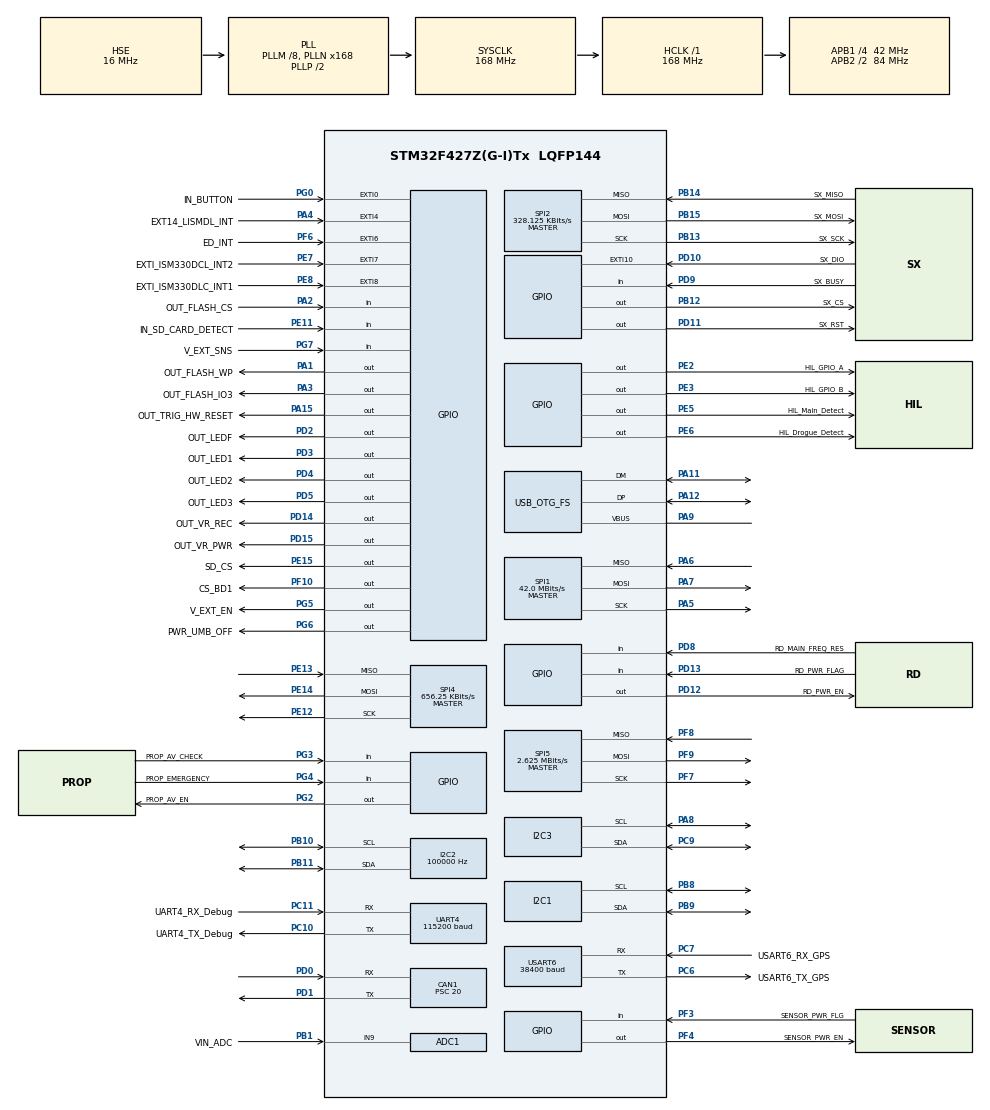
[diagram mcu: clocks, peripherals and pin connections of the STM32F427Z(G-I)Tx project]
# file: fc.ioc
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ADC1.Channel-1\#ChannelRegularConversion=ADC_CHANNEL_9
ADC1.NbrOfConversionFlag=1
ADC1.Rank-1\#ChannelRegularConversion=1
ADC1.SamplingTime-1\#ChannelRegularConversion=ADC_SAMPLETIME_3CYCLES
ADC1.master=1
CAN1.ABOM=DISABLE
CAN1.AWUM=DISABLE
CAN1.BS1=CAN_BS1_12TQ
CAN1.BS2=CAN_BS2_8TQ
CAN1.CalculateBaudRate=100000
CAN1.CalculateTimeBit=10000
CAN1.CalculateTimeQuantum=476.1904761904762
CAN1.Mode=CAN_MODE_NORMAL
CAN1.NART=DISABLE
CAN1.Prescaler=20
CAN1.RFLM=DISABLE
CAN1.SJW=CAN_SJW_1TQ
CAN1.TTCM=DISABLE
CAN1.TXFP=DISABLE
Dma.Request0=USART6_RX
Dma.Request1=SPI2_TX
Dma.Request2=SPI2_RX
Dma.SPI2_RX.2.Direction=DMA_PERIPH_TO_MEMORY
Dma.SPI2_RX.2.FIFOMode=DMA_FIFOMODE_DISABLE
Dma.SPI2_RX.2.Instance=DMA1_Stream3
Dma.SPI2_RX.2.MemDataAlignment=DMA_MDATAALIGN_BYTE
Dma.SPI2_RX.2.MemInc=DMA_MINC_ENABLE
Dma.SPI2_RX.2.Mode=DMA_NORMAL
Dma.SPI2_RX.2.PeriphDataAlignment=DMA_PDATAALIGN_BYTE
Dma.SPI2_RX.2.PeriphInc=DMA_PINC_DISABLE
Dma.SPI2_RX.2.Priority=DMA_PRIORITY_VERY_HIGH
Dma.SPI2_TX.1.Direction=DMA_MEMORY_TO_PERIPH
Dma.SPI2_TX.1.FIFOMode=DMA_FIFOMODE_DISABLE
Dma.SPI2_TX.1.Instance=DMA1_Stream4
Dma.SPI2_TX.1.MemDataAlignment=DMA_MDATAALIGN_BYTE
Dma.SPI2_TX.1.MemInc=DMA_MINC_ENABLE
Dma.SPI2_TX.1.Mode=DMA_NORMAL
Dma.SPI2_TX.1.PeriphDataAlignment=DMA_PDATAALIGN_BYTE
Dma.SPI2_TX.1.PeriphInc=DMA_PINC_DISABLE
Dma.SPI2_TX.1.Priority=DMA_PRIORITY_VERY_HIGH
Dma.USART6_RX.0.Direction=DMA_PERIPH_TO_MEMORY
Dma.USART6_RX.0.FIFOMode=DMA_FIFOMODE_DISABLE
Dma.USART6_RX.0.Instance=DMA2_Stream1
Dma.USART6_RX.0.MemDataAlignment=DMA_MDATAALIGN_BYTE
Dma.USART6_RX.0.MemInc=DMA_MINC_ENABLE
Dma.USART6_RX.0.Mode=DMA_NORMAL
Dma.USART6_RX.0.PeriphDataAlignment=DMA_PDATAALIGN_BYTE
Dma.USART6_RX.0.PeriphInc=DMA_PINC_DISABLE
Dma.USART6_RX.0.Priority=DMA_PRIORITY_MEDIUM
FATFS._CODE_PAGE=850
FATFS._FS_EXFAT=0
FATFS._FS_LOCK=2
FATFS._FS_MINIMIZE=0
FATFS._FS_NOFSINFO=0
FATFS._FS_NORTC=0
FATFS._FS_READONLY=0
FATFS._FS_REENTRANT=1
FATFS._FS_RPATH=0
FATFS._FS_TIMEOUT=1000
FATFS._FS_TINY=0
FATFS._LFN_UNICODE=0
FATFS._MAX_LFN=255
FATFS._MAX_SS=512
FATFS._MIN_SS=512
FATFS._MULTI_PARTITION=0
FATFS._STRF_ENCODE=3
FATFS._USE_CHMOD=0
FATFS._USE_EXPAND=0
FATFS._USE_FASTSEEK=1
FATFS._USE_FIND=0
FATFS._USE_FORWARD=0
FATFS._USE_LABEL=0
FATFS._USE_LFN=0
FATFS._USE_MKFS=1
FATFS._USE_STRFUNC=2
FATFS._USE_TRIM=0
FATFS._VOLUMES=1
FREERTOS.Tasks01=Telemetry,24,1024,StartTelemetry,Default,NULL,Dynamic,NULL,NULL;Radio,40,512,StartRadio,Default,NULL,Dynamic,NULL,NULL;Watchdog,48,512,StartWatchdog,Default,NULL,Dynamic,NULL,NULL;CAN,24,1024,StartCAN,Default,NULL,Dynamic,NULL,NULL
FREERTOS.configMINIMAL_STACK_SIZE=512
FREERTOS.configTIMER_TASK_PRIORITY=1
FREERTOS.configTIMER_TASK_STACK_DEPTH=512
FREERTOS.configUSE_DAEMON_TASK_STARTUP_HOOK=1
FREERTOS.configUSE_NEWLIB_REENTRANT=1
I2C2.AddressingMode=I2C_ADDRESSINGMODE_7BIT
I2C2.Analog_Filter=I2C_ANALOGFILTER_ENABLE
I2C2.ClockSpeed=100000
I2C2.DualAddressMode=I2C_DUALADDRESS_DISABLE
I2C2.GeneralCallMode=I2C_GENERALCALL_DISABLE
I2C2.I2C_Coeff_DF=0
I2C2.I2C_Mode=I2C_Standard
I2C2.NoStretchMode=I2C_NOSTRETCH_DISABLE
I2C2.OwnAddress=0
IWDG.Prescaler=IWDG_PRESCALER_32
IWDG.Reload=2999
Mcu.Family=STM32F4
Mcu.Name=STM32F427Z(G-I)Tx
Mcu.Package=LQFP144
NVIC.CAN1_RX0_IRQn=true\:5\:0\:false\:false\:true\:true\:true\:true\:true
NVIC.CAN1_RX1_IRQn=true\:5\:0\:false\:false\:true\:true\:true\:true\:true
NVIC.DMA1_Stream3_IRQn=true\:5\:0\:false\:false\:true\:true\:false\:true\:true
NVIC.DMA1_Stream4_IRQn=true\:5\:0\:false\:false\:true\:true\:false\:true\:true
NVIC.DMA2_Stream1_IRQn=true\:5\:0\:false\:false\:true\:false\:false\:true\:true
NVIC.EXTI15_10_IRQn=true\:5\:0\:false\:false\:true\:true\:true\:true\:true
NVIC.EXTI4_IRQn=true\:5\:0\:false\:false\:true\:true\:true\:true\:true
NVIC.EXTI9_5_IRQn=true\:5\:0\:false\:false\:true\:true\:true\:true\:true
NVIC.OTG_FS_IRQn=true\:5\:0\:false\:false\:true\:true\:false\:true\:true
NVIC.PriorityGroup=NVIC_PRIORITYGROUP_4
NVIC.TIM2_IRQn=true\:5\:0\:false\:false\:true\:true\:true\:true\:true
NVIC.TIM3_IRQn=true\:5\:0\:false\:false\:true\:true\:true\:true\:true
NVIC.TIM4_IRQn=true\:5\:0\:true\:false\:true\:true\:true\:true\:true
NVIC.TIM5_IRQn=true\:5\:0\:true\:false\:true\:true\:true\:true\:true
NVIC.UART4_IRQn=true\:5\:0\:true\:false\:true\:true\:true\:true\:true
PA1.GPIO_Label=OUT_FLASH_WP
PA1.Signal=GPIO_Output
PA11.Mode=Device_Only
PA11.Signal=USB_OTG_FS_DM
PA12.Mode=Device_Only
PA12.Signal=USB_OTG_FS_DP
PA13.Mode=Trace_Asynchronous_SW
PA13.Signal=SYS_JTMS-SWDIO
PA14.Mode=Trace_Asynchronous_SW
PA14.Signal=SYS_JTCK-SWCLK
PA15.GPIO_Label=OUT_TRIG_HW_RESET
PA15.Signal=GPIO_Output
PA2.GPIO_Label=OUT_FLASH_CS
PA2.Signal=GPIO_Input
PA3.GPIO_Label=OUT_FLASH_IO3
PA3.Signal=GPIO_Output
PA4.GPIO_Label=EXT14_LISMDL_INT
PA4.Signal=GPXTI4
PA5.Mode=Full_Duplex_Master
PA5.Signal=SPI1_SCK
PA6.Mode=Full_Duplex_Master
PA6.Signal=SPI1_MISO
PA7.Mode=Full_Duplex_Master
PA7.Signal=SPI1_MOSI
PA8.GPIO_Pu=GPIO_PULLUP
PA8.Mode=I2C
PA8.Signal=I2C3_SCL
PA9.Mode=Activate_VBUS
PA9.Signal=USB_OTG_FS_VBUS
PB1.GPIO_Label=VIN_ADC
PB1.Signal=ADCx_IN9
PB10.GPIO_Pu=GPIO_PULLUP
PB10.Mode=I2C
PB10.Signal=I2C2_SCL
PB11.GPIO_Pu=GPIO_PULLUP
PB11.Mode=I2C
PB11.Signal=I2C2_SDA
PB12.GPIO_Label=SX_CS
PB12.GPIO_PuPd=GPIO_PULLUP
PB12.GPIO_Speed=GPIO_SPEED_FREQ_VERY_HIGH
PB12.Signal=GPIO_Output
PB13.GPIO_Label=SX_SCK
PB13.GPIO_PuPd=GPIO_NOPULL
PB13.Mode=Full_Duplex_Master
PB13.Signal=SPI2_SCK
PB14.GPIO_Label=SX_MISO
PB14.GPIO_PuPd=GPIO_NOPULL
PB14.Mode=Full_Duplex_Master
PB14.Signal=SPI2_MISO
PB15.GPIO_Label=SX_MOSI
PB15.GPIO_PuPd=GPIO_NOPULL
PB15.Mode=Full_Duplex_Master
PB15.Signal=SPI2_MOSI
PB3.Mode=Trace_Asynchronous_SW
PB3.Signal=SYS_JTDO-SWO
PB8.GPIO_Pu=GPIO_PULLUP
PB8.Mode=I2C
PB8.Signal=I2C1_SCL
PB9.GPIO_Pu=GPIO_PULLUP
PB9.Mode=I2C
PB9.Signal=I2C1_SDA
PC10.GPIO_Label=UART4_TX_Debug
PC10.Mode=Asynchronous
PC10.Signal=UART4_TX
PC11.GPIO_Label=UART4_RX_Debug
PC11.Mode=Asynchronous
PC11.Signal=UART4_RX
PC14/OSC32_IN.Mode=LSE-External-Oscillator
PC14/OSC32_IN.Signal=RCC_OSC32_IN
PC15/OSC32_OUT.Mode=LSE-External-Oscillator
PC15/OSC32_OUT.Signal=RCC_OSC32_OUT
PC6.GPIO_Label=USART6_TX_GPS
PC6.Mode=Asynchronous
PC6.Signal=USART6_TX
PC7.GPIO_Label=USART6_RX_GPS
PC7.Mode=Asynchronous
PC7.Signal=USART6_RX
PC9.GPIO_Pu=GPIO_PULLUP
PC9.Mode=I2C
PC9.Signal=I2C3_SDA
PD0.Mode=CAN_Activate
PD0.Signal=CAN1_RX
PD1.Mode=CAN_Activate
PD1.Signal=CAN1_TX
PD10.GPIO_Label=SX_DIO
PD10.GPIO_PuPd=GPIO_PULLDOWN
PD10.Signal=GPXTI10
PD11.GPIO_Label=SX_RST
PD11.GPIO_PuPd=GPIO_NOPULL
PD11.PinState=GPIO_PIN_SET
PD11.Signal=GPIO_Output
PD12.GPIO_Label=RD_PWR_EN
PD12.Signal=GPIO_Output
PD13.GPIO_Label=RD_PWR_FLAG
PD13.Signal=GPIO_Input
PD14.GPIO_Label=OUT_VR_REC
PD14.Signal=GPIO_Output
PD15.GPIO_Label=OUT_VR_PWR
PD15.Signal=GPIO_Output
PD2.GPIO_Label=OUT_LEDF
PD2.Signal=GPIO_Output
PD3.GPIO_Label=OUT_LED1
PD3.Signal=GPIO_Output
PD4.GPIO_Label=OUT_LED2
PD4.Signal=GPIO_Output
PD5.GPIO_Label=OUT_LED3
PD5.Signal=GPIO_Output
PD8.GPIO_Label=RD_MAIN_FREQ_RES
PD8.Signal=GPIO_Input
PD9.GPIO_Label=SX_BUSY
PD9.GPIO_PuPd=GPIO_PULLDOWN
PD9.Signal=GPIO_Input
PE11.GPIO_Label=IN_SD_CARD_DETECT
PE11.Signal=GPIO_Input
PE12.Mode=Full_Duplex_Master
PE12.Signal=SPI4_SCK
PE13.Mode=Full_Duplex_Master
PE13.Signal=SPI4_MISO
PE14.Mode=Full_Duplex_Master
PE14.Signal=SPI4_MOSI
PE15.GPIO_Label=SD_CS
PE15.Signal=GPIO_Output
PE2.GPIO_Label=HIL_GPIO_A
PE2.Signal=GPIO_Output
PE3.GPIO_Label=HIL_GPIO_B
PE3.Signal=GPIO_Output
PE5.GPIO_Label=HIL_Main_Detect
PE5.Signal=GPIO_Output
PE6.GPIO_Label=HIL_Drogue_Detect
PE6.Signal=GPIO_Output
PE7.GPIO_Label=EXTI_ISM330DCL_INT2
PE7.Signal=GPXTI7
PE8.GPIO_Label=EXTI_ISM330DLC_INT1
PE8.Signal=GPXTI8
PF10.GPIO_Label=CS_BD1
PF10.Signal=GPIO_Output
PF3.GPIO_Label=SENSOR_PWR_FLG
PF3.Signal=GPIO_Input
PF4.GPIO_Label=SENSOR_PWR_EN
PF4.Signal=GPIO_Output
PF6.GPIO_Label=ED_INT
PF6.Signal=GPXTI6
PF7.GPIO_Mode=GPIO_MODE_AF_PP
PF7.GPIO_PuPd=GPIO_NOPULL
PF7.GPIO_Speed=GPIO_SPEED_FREQ_VERY_HIGH
PF7.Mode=Full_Duplex_Master
PF7.Signal=SPI5_SCK
PF8.GPIO_Mode=GPIO_MODE_AF_PP
PF8.GPIO_PuPd=GPIO_NOPULL
PF8.GPIO_Speed=GPIO_SPEED_FREQ_VERY_HIGH
PF8.Mode=Full_Duplex_Master
PF8.Signal=SPI5_MISO
PF9.GPIO_Mode=GPIO_MODE_AF_PP
PF9.GPIO_PuPd=GPIO_NOPULL
PF9.GPIO_Speed=GPIO_SPEED_FREQ_VERY_HIGH
PF9.Mode=Full_Duplex_Master
PF9.Signal=SPI5_MOSI
PG0.GPIO_Label=IN_BUTTON
PG0.Signal=GPXTI0
PG2.GPIO_Label=PROP_AV_EN
PG2.Signal=GPIO_Output
PG3.GPIO_Label=PROP_AV_CHECK
PG3.Signal=GPIO_Input
PG4.GPIO_Label=PROP_EMERGENCY
PG4.Signal=GPIO_Input
PG5.GPIO_Label=V_EXT_EN
PG5.Signal=GPIO_Output
PG6.GPIO_Label=PWR_UMB_OFF
PG6.Signal=GPIO_Output
PG7.GPIO_Label=V_EXT_SNS
PG7.Signal=GPIO_Input
PH0/OSC_IN.Mode=HSE-External-Oscillator
PH0/OSC_IN.Signal=RCC_OSC_IN
PH1/OSC_OUT.Mode=HSE-External-Oscillator
PH1/OSC_OUT.Signal=RCC_OSC_OUT
ProjectManager.HeapSize=0x200
ProjectManager.StackSize=0x400
ProjectManager.TargetToolchain=STM32CubeIDE
RCC.48MHZClocksFreq_Value=48000000
RCC.AHBFreq_Value=168000000
RCC.APB1CLKDivider=RCC_HCLK_DIV4
RCC.APB1Freq_Value=42000000
RCC.APB1TimFreq_Value=84000000
RCC.APB2CLKDivider=RCC_HCLK_DIV2
RCC.APB2Freq_Value=84000000
RCC.APB2TimFreq_Value=168000000
RCC.CortexFreq_Value=168000000
RCC.FLatency=FLASH_LATENCY_5
RCC.HCLKFreq_Value=168000000
RCC.HSE_VALUE=16000000
RCC.HSI_VALUE=16000000
RCC.PLLM=8
RCC.PLLN=168
RCC.PLLQ=7
RCC.PWR_Regulator_Voltage_Scale=PWR_REGULATOR_VOLTAGE_SCALE1
RCC.SYSCLKFreq_VALUE=168000000
RCC.SYSCLKSource=RCC_SYSCLKSOURCE_PLLCLK
RCC.VCOOutputFreq_Value=336000000
RTC.AsynchPrediv=127
RTC.HourFormat=RTC_HOURFORMAT_24
RTC.SynchPrediv=255
SH.ADCx_IN9.0=ADC1_IN9,IN9
SPI1.BaudRatePrescaler=SPI_BAUDRATEPRESCALER_2
SPI1.CalculateBaudRate=42.0 MBits/s
SPI1.Direction=SPI_DIRECTION_2LINES
SPI1.Mode=SPI_MODE_MASTER
SPI1.VirtualType=VM_MASTER
SPI2.BaudRatePrescaler=SPI_BAUDRATEPRESCALER_128
SPI2.CLKPhase=SPI_PHASE_1EDGE
SPI2.CLKPolarity=SPI_POLARITY_LOW
SPI2.CRCCalculation=SPI_CRCCALCULATION_DISABLE
SPI2.CalculateBaudRate=328.125 KBits/s
SPI2.DataSize=SPI_DATASIZE_8BIT
SPI2.Direction=SPI_DIRECTION_2LINES
SPI2.FirstBit=SPI_FIRSTBIT_MSB
SPI2.Mode=SPI_MODE_MASTER
SPI2.NSS=SPI_NSS_SOFT
SPI2.TIMode=SPI_TIMODE_DISABLE
SPI2.VirtualType=VM_MASTER
SPI4.BaudRatePrescaler=SPI_BAUDRATEPRESCALER_128
SPI4.CalculateBaudRate=656.25 KBits/s
SPI4.Direction=SPI_DIRECTION_2LINES
SPI4.Mode=SPI_MODE_MASTER
SPI4.VirtualType=VM_MASTER
SPI5.BaudRatePrescaler=SPI_BAUDRATEPRESCALER_32
SPI5.CalculateBaudRate=2.625 MBits/s
SPI5.Direction=SPI_DIRECTION_2LINES
SPI5.Mode=SPI_MODE_MASTER
SPI5.VirtualType=VM_MASTER
TIM1.Period=9999
TIM1.Prescaler=8399
TIM2.Period=4000 - 1
TIM2.Prescaler=42000-1
TIM3.Period=4000-1
TIM3.Prescaler=42000-1
TIM4.AutoReloadPreload=TIM_AUTORELOAD_PRELOAD_DISABLE
TIM4.ClockDivision=TIM_CLOCKDIVISION_DIV1
TIM4.CounterMode=TIM_COUNTERMODE_UP
TIM4.Period=59999
TIM4.Prescaler=41999
TIM4.TIM_MasterOutputTrigger=TIM_TRGO_RESET
TIM4.TIM_MasterSlaveMode=TIM_MASTERSLAVEMODE_DISABLE
TIM5.AutoReloadPreload=TIM_AUTORELOAD_PRELOAD_DISABLE
TIM5.ClockDivision=TIM_CLOCKDIVISION_DIV1
TIM5.CounterMode=TIM_COUNTERMODE_UP
TIM5.Period=1999
TIM5.Prescaler=41999
TIM5.TIM_MasterOutputTrigger=TIM_TRGO_RESET
TIM5.TIM_MasterSlaveMode=TIM_MASTERSLAVEMODE_DISABLE
UART4.BaudRate=115200
UART4.VirtualMode=Asynchronous
USART6.BaudRate=38400
USART6.Mode=MODE_TX_RX
USART6.OverSampling=UART_OVERSAMPLING_16
USART6.Parity=PARITY_NONE
USART6.StopBits=STOPBITS_1
USART6.VirtualMode=VM_ASYNC
USART6.WordLength=WORDLENGTH_8B
USB_DEVICE.APP_RX_DATA_SIZE-CDC_FS=2048
USB_DEVICE.APP_TX_DATA_SIZE-CDC_FS=2048
USB_DEVICE.CLASS_NAME_FS=CDC
USB_DEVICE.CONFIGURATION_STRING_CDC_FS=CDC Config
USB_DEVICE.INTERFACE_STRING_CDC_FS=CDC Interface
USB_DEVICE.LANGID_STRING-CDC_FS=1033
USB_DEVICE.MANUFACTURER_STRING-CDC_FS=STMicroelectronics
USB_DEVICE.PID_CDC_FS=22336
USB_DEVICE.PRODUCT_STRING_CDC_FS=STM32 Virtual ComPort
USB_DEVICE.USBD_DEBUG_LEVEL-CDC_FS=0
USB_DEVICE.USBD_MAX_NUM_CONFIGURATION-CDC_FS=1
USB_DEVICE.USBD_MAX_NUM_INTERFACES-CDC_FS=1
USB_DEVICE.USBD_MAX_STR_DESC_SIZ-CDC_FS=512
USB_DEVICE.USBD_SELF_POWERED-CDC_FS=1
USB_DEVICE.VID-CDC_FS=1155
USB_DEVICE.VirtualMode-CDC_FS=Cdc
USB_DEVICE.VirtualModeFS=Cdc_FS
USB_OTG_FS.Sof_enable=DISABLE
USB_OTG_FS.VirtualMode=Device_Only
USB_OTG_FS.low_power_enable=DISABLE
USB_OTG_FS.lpm_enable=DISABLE
USB_OTG_FS.vbus_sensing_enable=ENABLE
VP_FATFS_VS_Generic.Mode=User_defined
VP_FREERTOS_VS_CMSIS_V2.Mode=CMSIS_V2
VP_IWDG_VS_IWDG.Mode=IWDG_Activate
VP_RTC_VS_RTC_Activate.Mode=RTC_Enabled
VP_TIM1_VS_ClockSourceINT.Mode=Internal
VP_TIM2_VS_ClockSourceINT.Mode=Internal
VP_TIM3_VS_ClockSourceINT.Mode=Internal
VP_TIM4_VS_ClockSourceINT.Mode=Internal
VP_TIM5_VS_ClockSourceINT.Mode=Internal
VP_USB_DEVICE_VS_USB_DEVICE_CDC_FS.Mode=CDC_FS
board=custom

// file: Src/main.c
/* USER CODE BEGIN Header */
/**
  ******************************************************************************
  * @file           : main.c
  * @brief          : Main program body
  ******************************************************************************
  * @attention
  *
  * Copyright (c) 2026 STMicroelectronics.
  * All rights reserved.
  *
  * This software is licensed under terms that can be found in the LICENSE file
  * in the root directory of this software component.
  * If no LICENSE file comes with this software, it is provided AS-IS.
  *
  ******************************************************************************
  */
/* USER CODE END Header */
#include "main.h"
#include "cmsis_os.h"
#include "adc.h"
#include "can.h"
#include "dma.h"
#include "fatfs.h"
#include "i2c.h"
#include "rtc.h"
#include "spi.h"
#include "tim.h"
#include "usart.h"
#include "usb_device.h"
#include "gpio.h"

/* USER CODE BEGIN Includes */
#include "MRT_setup.h"
/* USER CODE END Includes */

void SystemClock_Config(void);
void MX_FREERTOS_Init(void);

int main(void)
{

  /* MCU Configuration--------------------------------------------------------*/

  /* Reset of all peripherals, Initializes the Flash interface and the Systick. */
  HAL_Init();

  /* Configure the system clock */
  SystemClock_Config();

  /* Initialize all configured peripherals */
  MX_GPIO_Init();
  MX_DMA_Init();
  MX_I2C2_Init();
  MX_SPI2_Init();
  MX_SPI5_Init();
  MX_TIM2_Init();
  MX_USART6_UART_Init();
  MX_ADC1_Init();
  MX_CAN1_Init();
  MX_FATFS_Init();
  MX_RTC_Init();
  MX_TIM5_Init();
  MX_TIM4_Init();
  MX_UART4_Init();
  MX_I2C3_Init();
  MX_SPI1_Init();
  MX_SPI4_Init();
  MX_TIM1_Init();
  MX_I2C1_Init();
  MX_TIM3_Init();

  /* Init scheduler */
  osKernelInitialize();  /* Call init function for freertos objects (in cmsis_os2.c) */
  MX_FREERTOS_Init();

  /* Start scheduler */
  osKernelStart();

  /* We should never get here as control is now taken by the scheduler */

  /* Infinite loop */
  while (1)
  {

  }
}

void SystemClock_Config(void)
{
  RCC_OscInitTypeDef RCC_OscInitStruct = {0};
  RCC_ClkInitTypeDef RCC_ClkInitStruct = {0};

  /** Configure the main internal regulator output voltage
  */
  __HAL_RCC_PWR_CLK_ENABLE();
  __HAL_PWR_VOLTAGESCALING_CONFIG(PWR_REGULATOR_VOLTAGE_SCALE1);

  /** Initializes the RCC Oscillators according to the specified parameters
  * in the RCC_OscInitTypeDef structure.
  */
  RCC_OscInitStruct.OscillatorType = RCC_OSCILLATORTYPE_LSI|RCC_OSCILLATORTYPE_HSE;
  RCC_OscInitStruct.HSEState = RCC_HSE_ON;
  RCC_OscInitStruct.LSIState = RCC_LSI_ON;
  RCC_OscInitStruct.PLL.PLLState = RCC_PLL_ON;
  RCC_OscInitStruct.PLL.PLLSource = RCC_PLLSOURCE_HSE;
  RCC_OscInitStruct.PLL.PLLM = 8;
  RCC_OscInitStruct.PLL.PLLN = 168;
  RCC_OscInitStruct.PLL.PLLP = RCC_PLLP_DIV2;
  RCC_OscInitStruct.PLL.PLLQ = 7;
  if (HAL_RCC_OscConfig(&RCC_OscInitStruct) != HAL_OK)
  {
    Error_Handler();
  }

  /** Initializes the CPU, AHB and APB buses clocks
  */
  RCC_ClkInitStruct.ClockType = RCC_CLOCKTYPE_HCLK|RCC_CLOCKTYPE_SYSCLK
                              |RCC_CLOCKTYPE_PCLK1|RCC_CLOCKTYPE_PCLK2;
  RCC_ClkInitStruct.SYSCLKSource = RCC_SYSCLKSOURCE_PLLCLK;
  RCC_ClkInitStruct.AHBCLKDivider = RCC_SYSCLK_DIV1;
  RCC_ClkInitStruct.APB1CLKDivider = RCC_HCLK_DIV4;
  RCC_ClkInitStruct.APB2CLKDivider = RCC_HCLK_DIV2;

  if (HAL_RCC_ClockConfig(&RCC_ClkInitStruct, FLASH_LATENCY_5) != HAL_OK)
  {
    Error_Handler();
  }
}

void Error_Handler(void)
{
  __disable_irq();
  while (1)
  {
  }
}

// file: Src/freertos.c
/* USER CODE BEGIN Header */
/**
  ******************************************************************************
  * File Name          : freertos.c
  * Description        : Code for freertos applications
  ******************************************************************************
  * @attention
  *
  * Copyright (c) 2026 STMicroelectronics.
  * All rights reserved.
  *
  * This software is licensed under terms that can be found in the LICENSE file
  * in the root directory of this software component.
  * If no LICENSE file comes with this software, it is provided AS-IS.
  *
  ******************************************************************************
  */
/* USER CODE END Header */

#include "FreeRTOS.h"
#include "task.h"
#include "main.h"
#include "cmsis_os.h"

/* USER CODE BEGIN Includes */
#include "MRT_setup.h"
/* USER CODE END Includes */

/* Definitions for Telemetry */
osThreadId_t TelemetryHandle;
const osThreadAttr_t Telemetry_attributes = {
  .name = "Telemetry",
  .stack_size = 1024 * 4,
  .priority = (osPriority_t) osPriorityNormal,
};
/* Definitions for Radio */
osThreadId_t RadioHandle;
const osThreadAttr_t Radio_attributes = {
  .name = "Radio",
  .stack_size = 512 * 4,
  .priority = (osPriority_t) osPriorityHigh,
};
/* Definitions for Watchdog */
osThreadId_t WatchdogHandle;
const osThreadAttr_t Watchdog_attributes = {
  .name = "Watchdog",
  .stack_size = 512 * 4,
  .priority = (osPriority_t) osPriorityRealtime,
};
/* Definitions for CAN */
osThreadId_t CANHandle;
const osThreadAttr_t CAN_attributes = {
  .name = "CAN",
  .stack_size = 1024 * 4,
  .priority = (osPriority_t) osPriorityNormal,
};

void StartTelemetry(void *argument);
void StartRadio(void *argument);
void StartWatchdog(void *argument);
void StartCAN(void *argument);

extern void MX_USB_DEVICE_Init(void);
void MX_FREERTOS_Init(void); /* (MISRA C 2004 rule 8.1) */

/* Hook prototypes */
void vApplicationDaemonTaskStartupHook(void);

/* USER CODE BEGIN DAEMON_TASK_STARTUP_HOOK */
void vApplicationDaemonTaskStartupHook(void)
{

    /* creation of Telemetry */
	TelemetryHandle = osThreadNew(StartTelemetry, NULL, &Telemetry_attributes);
}
/* USER CODE END DAEMON_TASK_STARTUP_HOOK */

void MX_FREERTOS_Init(void) {
  /* USER CODE BEGIN Init */
    /* init code for USB_DEVICE */
    MX_USB_DEVICE_Init();
  /* USER CODE END Init */

  /* USER CODE BEGIN RTOS_QUEUES */
  /* add queues, ... */
  #ifdef THREADS_NOT_CREATED_HERE
  /* USER CODE END RTOS_QUEUES */

  /* Create the thread(s) */
  /* creation of Telemetry */
  TelemetryHandle = osThreadNew(StartTelemetry, NULL, &Telemetry_attributes);

  /* creation of Radio */
  RadioHandle = osThreadNew(StartRadio, NULL, &Radio_attributes);

  /* creation of Watchdog */
  WatchdogHandle = osThreadNew(StartWatchdog, NULL, &Watchdog_attributes);

  /* creation of CAN */
  CANHandle = osThreadNew(StartCAN, NULL, &CAN_attributes);

  /* USER CODE BEGIN RTOS_THREADS */
  /* add threads, ... */
  #endif
  /* USER CODE END RTOS_THREADS */

}

void StartTelemetry(void *argument)
{
  /* init code for USB_DEVICE */
  MX_USB_DEVICE_Init();
  /* USER CODE BEGIN StartTelemetry */
    MRT_setup();
  /* USER CODE END StartTelemetry */
}

void StartRadio(void *argument)
{
  for(;;)
  {
    osDelay(1);
  }
}

void StartWatchdog(void *argument)
{
  for(;;)
  {
    osDelay(1);
  }
}

void StartCAN(void *argument)
{
  for(;;)
  {
    osDelay(1);
  }
}
